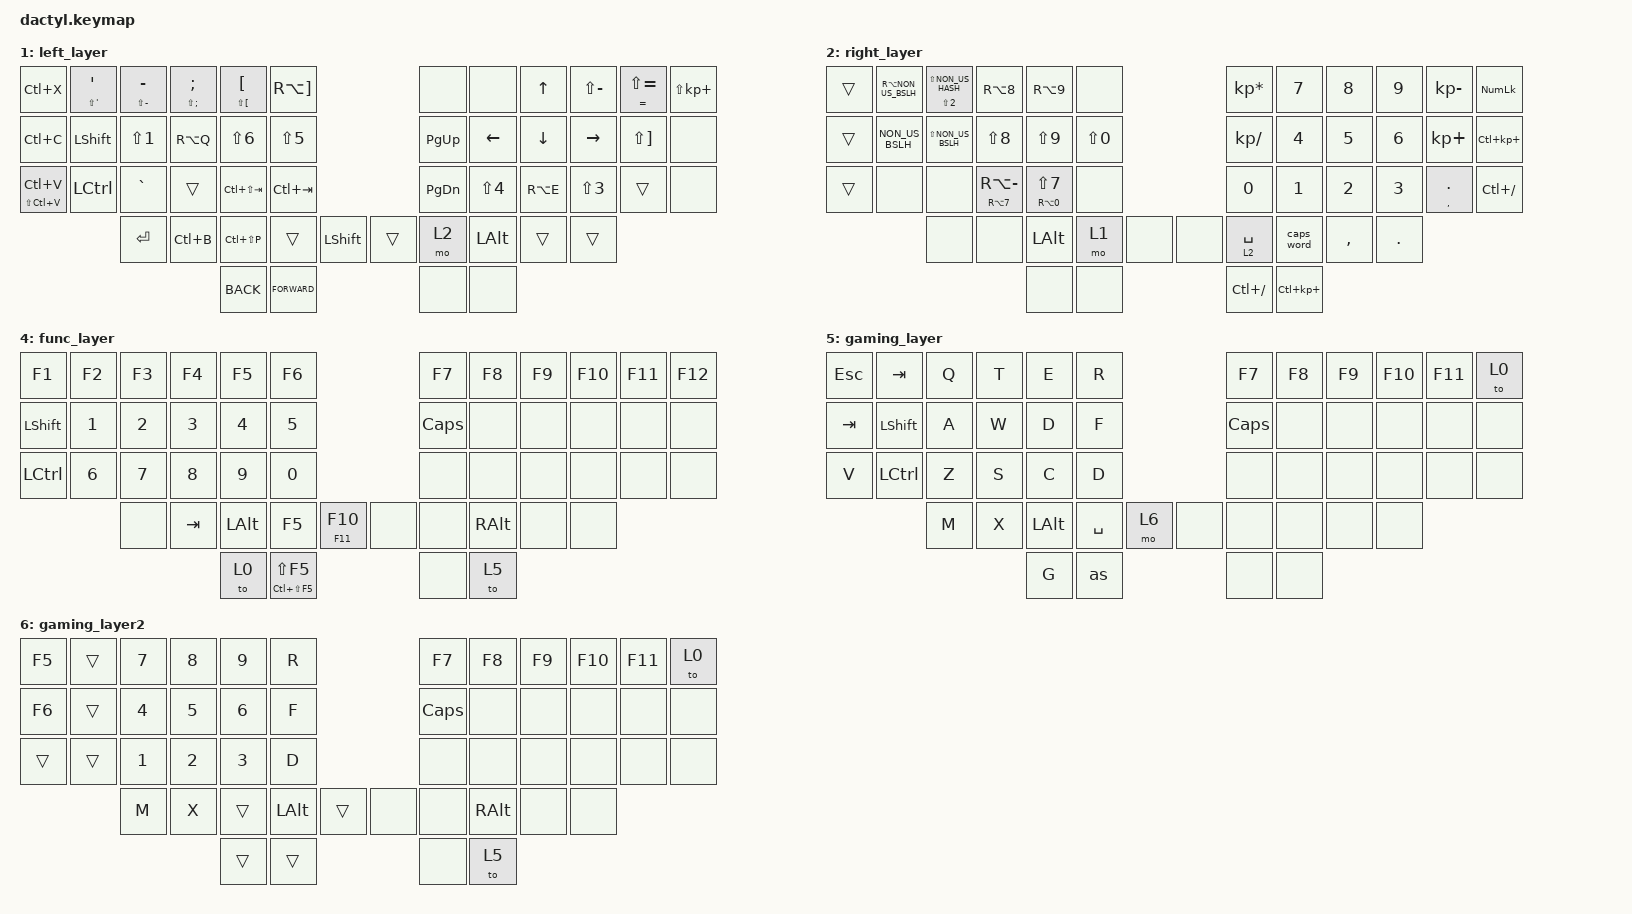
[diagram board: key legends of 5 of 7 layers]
#include <behaviors.dtsi>
#include <dt-bindings/zmk/bt.h>
#include <dt-bindings/zmk/keys.h>
#include <dt-bindings/zmk/outputs.h>


#define MODTIME 25

&mt {
    tapping-term-ms = <145>;
    quick_tap_ms = <140>;
};

/ {
    conditional_layers {
        compatible = "zmk,conditional-layers";
        tri_layer {
            if-layers = <1 2>;
            then-layer = <3>;
        };
    };
};
/ {

    combos {
        compatible = "zmk,combos";
        combo_enter {
            timeout-ms = <MODTIME>;
            key-positions = <32 33>;
            bindings = <&mt LS(ENTER) ENTER>;
            layers = <0>;
        };
        combo_ctl_bsp {
            timeout-ms = <MODTIME>;
            key-positions = <32 31>;
            bindings = <&kp LC(BSPC) >;
            layers = <0>;
        };
        combo_end {
            timeout-ms = <MODTIME>;
            key-positions = <20 21>;
            bindings = <&kp END>;
            layers = <0>;
        };
        combo_home {
            timeout-ms = <MODTIME>;
            key-positions = <19 20>;
            bindings = <&kp HOME>;
            layers = <0>;
        }; 
    };
};
/ {
    macros {
        line_select: line_select {
            compatible = "zmk,behavior-macro";
            label = "line_select";
            #binding-cells = <0>;
            wait-ms = <30>;
            tap-ms = <60>;
            bindings = < &kp HOME &kp LS(END)>;
        };
        quote_word: quote_word {
            compatible = "zmk,behavior-macro";
            label = "quote_word";
            #binding-cells = <0>;
            wait-ms = <30>;
            tap-ms = <60>;
            bindings = < &kp LC(LS(LEFT)) &kp LS(NON_US_HASH) &kp RIGHT>;
        };
        double_quote_word: double_quote_word {
            compatible = "zmk,behavior-macro";
            label = "double_quote_word";
            #binding-cells = <0>;
            wait-ms = <30>;
            tap-ms = <60>;
            bindings = < &kp LC(LS(LEFT)) &kp LS(N2) &kp RIGHT>;
        };
        paste_obsidian_link: paste_obsidian_link {
            compatible = "zmk,behavior-macro";
            label = "paste_obsidian_link";
            #binding-cells = <0>;
            wait-ms = <80>;
            tap-ms = <60>;
            bindings = 
            <&kp RA(N8) &kp RIGHT &kp RIGHT &kp LS(N8)>,
            <&kp LC(V)>,
            <&kp RIGHT>;
        }; 
    };

    behaviors {
        as: auto_shift {
                compatible = "zmk,behavior-hold-tap";
                label = "AUTO_SHIFT";
                #binding-cells = <2>;
                tapping_term_ms = <180>;
                quick_tap_ms = <0>;
                flavor = "tap-preferred";
                //hold-trigger-key-positions = <0>;    
                bindings = <&kp>, <&kp>; 
            };
    };
};
    &caps_word {
        continue-list = <UNDERSCORE MINUS BACKSPACE DELETE LEFT RIGHT LS(FSLH) FSLH>;
    };
/{
    keymap {
        compatible = "zmk,keymap";
    
// 0
        default_layer {

            bindings = <
    &kp LSHIFT          &as LS(Q) Q     &as LS(W) W     &as LS(F) F     &as LS(P) P     &as LS(B) B                                                 &as LS(J) J      &as LS(L) L     &as LS(U) U             &as LS(Z) Z      &as LS(NON_US_HASH) NON_US_HASH    &as LC(G) LC(F)
    &as LS(TAB) TAB     &as LS(A) A     &as LS(R) R     &as LS(S) S     &as LS(T) T     &as LS(G) G                                                 &as LS(M) M      &as LS(N) N     &as LS(E) E             &as LS(I) I      &as LS(O) O                       &as LC(RET) RET
    &kp LCTRL           &as LS(Y) Y     &as LS(X) X     &as LS(C) C     &as LS(D) D     &as LS(V) V                                                 &as LS(K) K      &as LS(H) H     &as LS(COMMA) COMMA     &as LS(DOT) DOT  &kp DOWN                           &kp RIGHT
                                     &kp LGUI        &kp LG(LS(S))   &mt LALT ESC   &lt 1 SPACE       &kp BSPC                           &mt LSHIFT DELETE        &lt 2 SPACE     &as LS(FSLH) FSLH   &kp LEFT                &kp UP
                                                                    &kp LS(LC(LALT))       &mt LS(F12) F12                                   &mt LS(LA(LC(LGUI))) K_APP             &caps_word
            >;
        };
// 
        left_layer {

            bindings = <
    &kp LC(X)               &as LS(SQT) SQT &as LS(MINUS) MINUS     &as LS(SEMI) SEMI   &as LS(LBKT) LBKT  &kp RA(RBKT)                                     &none           &none          &kp UP      &kp LS(MINUS)    &as EQUAL LS(EQUAL)      &kp LS(KP_PLUS)
    &kp LC(C)               &kp LSHIFT      &kp LS(N1)              &kp RA(Q)           &kp LS(N6)         &kp LS(N5)                                       &kp PAGE_UP     &kp LEFT        &kp DOWN    &kp RIGHT        &kp LS(RBKT)           &none
    &as LS(LC(V)) LC(V)     &kp LCTRL       &kp GRAVE               &trans              &kp LC(LS(TAB))    &kp LC(TAB)                                      &kp PAGE_DOWN   &kp LS(N4)      &kp RA(E)   &kp LS(N3)       &trans                 &none
                                &kp RET               &kp LC(B)           &kp LC(LS(P))          &trans         &kp LSHIFT               &trans        &mo 2          &kp LALT    &trans         &trans
                                                                                        &kp K_BACK                &kp K_FORWARD                                       &none       &none
        >; 
        };

//2
        right_layer {

            bindings = <
    &trans   &kp RA(NON_US_BSLH)     &as LS(N2) LS(NON_US_HASH)  &kp RA(N8)          &kp RA(N9)         &none                                                &kp KP_ASTERISK     &kp N7     &kp N8       &kp N9      &kp KP_MINUS   &kp KP_NUMLOCK
    &trans   &kp NON_US_BSLH        &kp LS(NON_US_BSLH)         &kp LS(N8)          &kp LS(N9)         &kp LS(N0)                                           &kp KP_SLASH        &kp N4     &kp N5       &kp N6      &kp KP_PLUS    &kp LC(KP_PLUS)
    &trans   &none                  &none                       &as RA(N7) RA(MINUS) &as RA(N0) LS(N7)  &none                                               &kp N0              &kp N1     &kp N2       &kp N3      &as COMMA DOT  &kp LC(FSLH)
                                 &none                       &none                &kp LALT          &mo 1       &none                   &none       &lt 2 SPACE        &caps_word           &kp COMMA       &kp DOT
                                                                                        &none           &none                                  &kp LC(FSLH)        &kp LC(KP_PLUS)
            >;
        };
//3
        both_layer {

            bindings = <
    &kp LG(LS(T))       &none   &as quote_word double_quote_word &none  &kp C_PLAY_PAUSE  &kp C_VOL_UP                               &bt BT_CLR &line_select        &kp LC(HOME)    &kp LS(END)         &none           &sl 4
    &none               &none   &mt LC(F2) F2                   &none  &none         &kp kp C_VOL_DN                                &none      &kp LS(LC(LEFT))    &kp LC(END)     &kp LS(LC(RIGHT))   &none           &bt BT_SEL 5
    &paste_obsidian_link &none   &none                           &none  &kp LA(LEFT)    &kp LA(RIGHT)                      &none      &bt BT_SEL 0        &bt BT_SEL 1    &bt BT_SEL 2        &bt BT_SEL 3 &bt BT_SEL 4
                            &none   &none                        &none          &trans     &to 5        &none      &trans     &none    &none           &none
                                                                        &to 4      &none                                      &none     &none
            >;
        };
//4
        func_layer {

            bindings = <
    &kp F1      &kp F2      &kp F3    &kp F4      &kp F5     &kp F6                                               &kp F7        &kp F8  &kp F9   &kp F10  &kp F11  &kp F12
    &kp LSHIFT  &kp N1      &kp N2    &kp N3      &kp N4     &kp N5                                               &kp CAPSLOCK &none   &none    &none    &none    &none
    &kp LCTRL   &kp N6      &kp N7    &kp N8      &kp N9     &kp N0                                               &none         &none   &none    &none    &none    &none
                            &none     &kp TAB     &kp LALT   &kp F5    &as F11 F10                      &none  &none     &kp RALT    &none       &none
                                                    &to 0   &as LC(LS(F5)) LS(F5)                                        &none   &to 5
            >;
        };
//5
        gaming_layer {

            bindings = <
    &kp ESC &kp TAB   &kp Q   &kp T    &kp E      &kp R                                                      &kp F7        &kp F8  &kp F9   &kp F10  &kp F11  &to 0
    &kp TAB &kp LSHFT &kp A   &kp W    &kp D      &kp F                                                      &kp CAPSLOCK &none   &none    &none    &none    &none
    &kp V   &kp LCTRL &kp Z   &kp S    &kp C      &kp D                                                     &none         &none   &none    &none    &none    &none
                        &kp M   &kp X       &kp LALT    &kp SPACE    &mo 6                      &none  &none     &none    &none       &none
                                                    &kp G   &as                                         &none   &none
            >;
        };
//6 
    gaming_layer2 {

            bindings = <
    &kp F5 &trans &kp N7   &kp N8    &kp N9      &kp R                                                      &kp F7        &kp F8  &kp F9   &kp F10  &kp F11  &to 0
    &kp F6 &trans &kp N4   &kp N5    &kp N6      &kp F                                                      &kp CAPSLOCK &none   &none    &none    &none    &none
    &trans &trans &kp N1   &kp N2    &kp N3      &kp D                                                     &none         &none   &none    &none    &none    &none
                        &kp M   &kp X       &trans    &kp LALT    &trans                      &none  &none     &kp RALT    &none       &none
                                                    &trans   &trans                                         &none   &to 5
            >;
        };

    };
};
